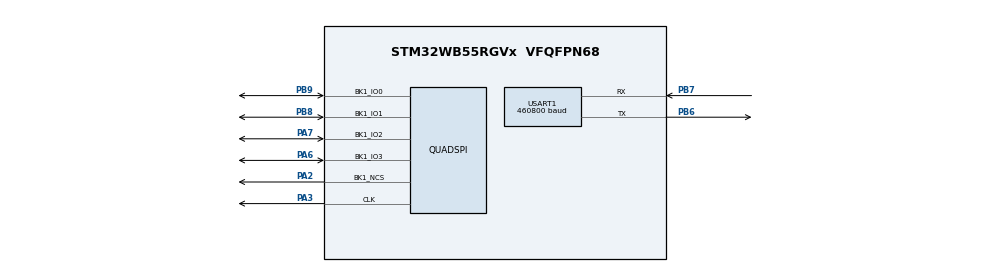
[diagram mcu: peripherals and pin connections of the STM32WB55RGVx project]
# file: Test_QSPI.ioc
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Dma.QUADSPI.1.Direction=DMA_PERIPH_TO_MEMORY
Dma.QUADSPI.1.EventEnable=DISABLE
Dma.QUADSPI.1.Instance=DMA1_Channel2
Dma.QUADSPI.1.MemDataAlignment=DMA_MDATAALIGN_BYTE
Dma.QUADSPI.1.MemInc=DMA_MINC_ENABLE
Dma.QUADSPI.1.Mode=DMA_NORMAL
Dma.QUADSPI.1.PeriphDataAlignment=DMA_PDATAALIGN_BYTE
Dma.QUADSPI.1.PeriphInc=DMA_PINC_DISABLE
Dma.QUADSPI.1.Polarity=HAL_DMAMUX_REQ_GEN_RISING
Dma.QUADSPI.1.Priority=DMA_PRIORITY_LOW
Dma.QUADSPI.1.RequestNumber=1
Dma.QUADSPI.1.SignalID=NONE
Dma.QUADSPI.1.SyncEnable=DISABLE
Dma.QUADSPI.1.SyncPolarity=HAL_DMAMUX_SYNC_NO_EVENT
Dma.QUADSPI.1.SyncRequestNumber=1
Dma.QUADSPI.1.SyncSignalID=NONE
Dma.Request0=USART1_TX
Dma.Request1=QUADSPI
Dma.USART1_TX.0.Direction=DMA_MEMORY_TO_PERIPH
Dma.USART1_TX.0.EventEnable=DISABLE
Dma.USART1_TX.0.Instance=DMA1_Channel1
Dma.USART1_TX.0.MemDataAlignment=DMA_MDATAALIGN_BYTE
Dma.USART1_TX.0.MemInc=DMA_MINC_ENABLE
Dma.USART1_TX.0.Mode=DMA_NORMAL
Dma.USART1_TX.0.PeriphDataAlignment=DMA_PDATAALIGN_BYTE
Dma.USART1_TX.0.PeriphInc=DMA_PINC_DISABLE
Dma.USART1_TX.0.Polarity=HAL_DMAMUX_REQ_GEN_RISING
Dma.USART1_TX.0.Priority=DMA_PRIORITY_LOW
Dma.USART1_TX.0.RequestNumber=1
Dma.USART1_TX.0.SignalID=NONE
Dma.USART1_TX.0.SyncEnable=DISABLE
Dma.USART1_TX.0.SyncPolarity=HAL_DMAMUX_SYNC_NO_EVENT
Dma.USART1_TX.0.SyncRequestNumber=1
Dma.USART1_TX.0.SyncSignalID=NONE
Mcu.Family=STM32WB
Mcu.Name=STM32WB55RGVx
Mcu.Package=VFQFPN68
NVIC.DMA1_Channel1_IRQn=true\:0\:0\:false\:false\:true\:false\:true
NVIC.DMA1_Channel2_IRQn=true\:0\:0\:false\:false\:true\:false\:true
NVIC.LPTIM1_IRQn=true\:0\:0\:false\:false\:true\:true\:true
NVIC.PriorityGroup=NVIC_PRIORITYGROUP_4
NVIC.QUADSPI_IRQn=true\:0\:0\:false\:false\:true\:true\:true
NVIC.TIM1_TRG_COM_TIM17_IRQn=true\:15\:0\:false\:false\:true\:false\:true
NVIC.TimeBase=TIM1_TRG_COM_TIM17_IRQn
NVIC.TimeBaseIP=TIM17
OSC_IN.Mode=HSE-External-Oscillator
OSC_IN.Signal=RCC_OSC_IN
OSC_OUT.Mode=HSE-External-Oscillator
OSC_OUT.Signal=RCC_OSC_OUT
PA2.Mode=Single Bank 1
PA2.Signal=QUADSPI_BK1_NCS
PA3.Mode=Single Bank 1
PA3.Signal=QUADSPI_CLK
PA6.Mode=Single Bank 1
PA6.Signal=QUADSPI_BK1_IO3
PA7.Mode=Single Bank 1
PA7.Signal=QUADSPI_BK1_IO2
PB6.Mode=Asynchronous
PB6.Signal=USART1_TX
PB7.Mode=Asynchronous
PB7.Signal=USART1_RX
PB8.Mode=Single Bank 1
PB8.Signal=QUADSPI_BK1_IO1
PB9.Mode=Single Bank 1
PB9.Signal=QUADSPI_BK1_IO0
PC14-OSC32_IN.Mode=LSE-External-Oscillator
PC14-OSC32_IN.Signal=RCC_OSC32_IN
PC15-OSC32_OUT.Mode=LSE-External-Oscillator
PC15-OSC32_OUT.Signal=RCC_OSC32_OUT
ProjectManager.HeapSize=0x2000
ProjectManager.StackSize=0x2000
ProjectManager.TargetToolchain=STM32CubeIDE
QUADSPI.ClockPrescaler=0
RCC.ADCFreq_Value=128000000
RCC.AHBFreq_Value=32000000
RCC.APB1Freq_Value=32000000
RCC.APB1TimFreq_Value=32000000
RCC.APB2Freq_Value=32000000
RCC.APB2TimFreq_Value=32000000
RCC.APB3Freq_Value=16000000
RCC.CortexFreq_Value=32000000
RCC.HCLKFreq_Value=32000000
RCC.HSE_VALUE=32000000
RCC.HSI48_VALUE=48000000
RCC.HSI_VALUE=16000000
RCC.LPTIM1CLockSelection=RCC_LPTIM1CLKSOURCE_LSI
RCC.MSIClockRange=RCC_MSIRANGE_10
RCC.RTCClockSelection=RCC_RTCCLKSOURCE_LSE
RCC.SMPSCLockSelectionVirtual=RCC_SMPSCLKSOURCE_HSI
RCC.SMPSCLockSelectionVirtualVirtual=RCC_SMPSCLKSOURCE_HSI
RCC.SMPSDivider=1
RCC.SYSCLKFreq_VALUE=32000000
RCC.USBFreq_Value=128000000
RCC.VCOOutputFreq_Value=256000000
USART1.BaudRate=460800
USART1.VirtualMode-Asynchronous=VM_ASYNC
VP_LPTIM1_VS_LPTIM_counterModeInternalClock.Mode=Counts__internal_clock_event_00
VP_SYS_VS_tim17.Mode=TIM17
board=P-NUCLEO-WB55-Nucleo

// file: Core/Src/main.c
/* USER CODE BEGIN Header */
/**
  ******************************************************************************
  * @file           : main.c
  * @brief          : Main program body
  ******************************************************************************
  * @attention
  *
  * <h2><center>&copy; Copyright (c) 2021 STMicroelectronics.
  * All rights reserved.</center></h2>
  *
  * This software component is licensed by ST under BSD 3-Clause license,
  * the "License"; You may not use this file except in compliance with the
  * License. You may obtain a copy of the License at:
  *                        opensource.org/licenses/BSD-3-Clause
  *
  ******************************************************************************
  */
/* USER CODE END Header */
#include <component_storage.h>
#include "main.h"

LPTIM_HandleTypeDef hlptim1;

UART_HandleTypeDef huart1;
DMA_HandleTypeDef hdma_usart1_tx;

void SystemClock_Config(void);
static void MX_GPIO_Init(void);
static void MX_DMA_Init(void);
static void MX_QUADSPI_Init(void);
static void MX_USART1_UART_Init(void);
static void MX_LPTIM1_Init(void);
/* USER CODE BEGIN PFP */
int __io_putchar(int ch)
{
	uint8_t character = ch & 0xFF;
	HAL_UART_Transmit(&huart1, &character, 1, HAL_MAX_DELAY);
	return ch;
}
/* USER CODE END PFP */

/* USER CODE BEGIN 0 */
volatile uint32_t counter = 0;
/* USER CODE END 0 */

int main(void)
{

  /* MCU Configuration--------------------------------------------------------*/

  /* Reset of all peripherals, Initializes the Flash interface and the Systick. */
  HAL_Init();

  /* Configure the system clock */
  SystemClock_Config();

  /* Initialize all configured peripherals */
  MX_GPIO_Init();
  MX_DMA_Init();
  MX_QUADSPI_Init();
  MX_USART1_UART_Init();
  MX_LPTIM1_Init();
  /* USER CODE BEGIN 2 */
//	HAL_LPTIM_PWM_Start_IT(&hlptim1, 32767, 16000);
	COMPONENT_STORAGE_Initialize();

  /* USER CODE END 2 */

  /* Infinite loop */
	while (1)
	{

	}
}

void HAL_LPTIM_AutoReloadMatchCallback(LPTIM_HandleTypeDef *hlptim)
{

}

void SystemClock_Config(void)
{
  RCC_OscInitTypeDef RCC_OscInitStruct = {0};
  RCC_ClkInitTypeDef RCC_ClkInitStruct = {0};
  RCC_PeriphCLKInitTypeDef PeriphClkInitStruct = {0};

  /** Configure the main internal regulator output voltage
  */
  __HAL_PWR_VOLTAGESCALING_CONFIG(PWR_REGULATOR_VOLTAGE_SCALE1);
  /** Initializes the RCC Oscillators according to the specified parameters
  * in the RCC_OscInitTypeDef structure.
  */
  RCC_OscInitStruct.OscillatorType = RCC_OSCILLATORTYPE_HSI|RCC_OSCILLATORTYPE_LSI1
                              |RCC_OSCILLATORTYPE_HSE|RCC_OSCILLATORTYPE_MSI;
  RCC_OscInitStruct.HSEState = RCC_HSE_ON;
  RCC_OscInitStruct.HSIState = RCC_HSI_ON;
  RCC_OscInitStruct.MSIState = RCC_MSI_ON;
  RCC_OscInitStruct.HSICalibrationValue = RCC_HSICALIBRATION_DEFAULT;
  RCC_OscInitStruct.MSICalibrationValue = RCC_MSICALIBRATION_DEFAULT;
  RCC_OscInitStruct.MSIClockRange = RCC_MSIRANGE_10;
  RCC_OscInitStruct.LSIState = RCC_LSI_ON;
  RCC_OscInitStruct.PLL.PLLState = RCC_PLL_NONE;
  if (HAL_RCC_OscConfig(&RCC_OscInitStruct) != HAL_OK)
  {
    Error_Handler();
  }
  /** Configure the SYSCLKSource, HCLK, PCLK1 and PCLK2 clocks dividers
  */
  RCC_ClkInitStruct.ClockType = RCC_CLOCKTYPE_HCLK4|RCC_CLOCKTYPE_HCLK2
                              |RCC_CLOCKTYPE_HCLK|RCC_CLOCKTYPE_SYSCLK
                              |RCC_CLOCKTYPE_PCLK1|RCC_CLOCKTYPE_PCLK2;
  RCC_ClkInitStruct.SYSCLKSource = RCC_SYSCLKSOURCE_MSI;
  RCC_ClkInitStruct.AHBCLKDivider = RCC_SYSCLK_DIV1;
  RCC_ClkInitStruct.APB1CLKDivider = RCC_HCLK_DIV1;
  RCC_ClkInitStruct.APB2CLKDivider = RCC_HCLK_DIV1;
  RCC_ClkInitStruct.AHBCLK2Divider = RCC_SYSCLK_DIV1;
  RCC_ClkInitStruct.AHBCLK4Divider = RCC_SYSCLK_DIV1;

  if (HAL_RCC_ClockConfig(&RCC_ClkInitStruct, FLASH_LATENCY_1) != HAL_OK)
  {
    Error_Handler();
  }
  /** Initializes the peripherals clocks
  */
  PeriphClkInitStruct.PeriphClockSelection = RCC_PERIPHCLK_SMPS|RCC_PERIPHCLK_USART1
                              |RCC_PERIPHCLK_LPTIM1;
  PeriphClkInitStruct.Usart1ClockSelection = RCC_USART1CLKSOURCE_PCLK2;
  PeriphClkInitStruct.Lptim1ClockSelection = RCC_LPTIM1CLKSOURCE_LSI;
  PeriphClkInitStruct.SmpsClockSelection = RCC_SMPSCLKSOURCE_HSI;
  PeriphClkInitStruct.SmpsDivSelection = RCC_SMPSCLKDIV_RANGE0;
  if (HAL_RCCEx_PeriphCLKConfig(&PeriphClkInitStruct) != HAL_OK)
  {
    Error_Handler();
  }
}

static void MX_LPTIM1_Init(void)
{

  hlptim1.Instance = LPTIM1;
  hlptim1.Init.Clock.Source = LPTIM_CLOCKSOURCE_APBCLOCK_LPOSC;
  hlptim1.Init.Clock.Prescaler = LPTIM_PRESCALER_DIV1;
  hlptim1.Init.Trigger.Source = LPTIM_TRIGSOURCE_SOFTWARE;
  hlptim1.Init.OutputPolarity = LPTIM_OUTPUTPOLARITY_HIGH;
  hlptim1.Init.UpdateMode = LPTIM_UPDATE_IMMEDIATE;
  hlptim1.Init.CounterSource = LPTIM_COUNTERSOURCE_INTERNAL;
  hlptim1.Init.Input1Source = LPTIM_INPUT1SOURCE_GPIO;
  hlptim1.Init.Input2Source = LPTIM_INPUT2SOURCE_GPIO;
  if (HAL_LPTIM_Init(&hlptim1) != HAL_OK)
  {
    Error_Handler();
  }

}

static void MX_QUADSPI_Init(void)
{

  /* QUADSPI parameter configuration*/

}

static void MX_USART1_UART_Init(void)
{

  huart1.Instance = USART1;
  huart1.Init.BaudRate = 460800;
  huart1.Init.WordLength = UART_WORDLENGTH_8B;
  huart1.Init.StopBits = UART_STOPBITS_1;
  huart1.Init.Parity = UART_PARITY_NONE;
  huart1.Init.Mode = UART_MODE_TX_RX;
  huart1.Init.HwFlowCtl = UART_HWCONTROL_NONE;
  huart1.Init.OverSampling = UART_OVERSAMPLING_16;
  huart1.Init.OneBitSampling = UART_ONE_BIT_SAMPLE_DISABLE;
  huart1.Init.ClockPrescaler = UART_PRESCALER_DIV1;
  huart1.AdvancedInit.AdvFeatureInit = UART_ADVFEATURE_NO_INIT;
  if (HAL_UART_Init(&huart1) != HAL_OK)
  {
    Error_Handler();
  }
  if (HAL_UARTEx_SetTxFifoThreshold(&huart1, UART_TXFIFO_THRESHOLD_1_8) != HAL_OK)
  {
    Error_Handler();
  }
  if (HAL_UARTEx_SetRxFifoThreshold(&huart1, UART_RXFIFO_THRESHOLD_1_8) != HAL_OK)
  {
    Error_Handler();
  }
  if (HAL_UARTEx_DisableFifoMode(&huart1) != HAL_OK)
  {
    Error_Handler();
  }

}

static void MX_DMA_Init(void)
{

  /* DMA controller clock enable */
  __HAL_RCC_DMAMUX1_CLK_ENABLE();
  __HAL_RCC_DMA1_CLK_ENABLE();

  /* DMA interrupt init */
  /* DMA1_Channel1_IRQn interrupt configuration */
  HAL_NVIC_SetPriority(DMA1_Channel1_IRQn, 0, 0);
  HAL_NVIC_EnableIRQ(DMA1_Channel1_IRQn);
  /* DMA1_Channel2_IRQn interrupt configuration */
  HAL_NVIC_SetPriority(DMA1_Channel2_IRQn, 0, 0);
  HAL_NVIC_EnableIRQ(DMA1_Channel2_IRQn);

}

static void MX_GPIO_Init(void)
{

  /* GPIO Ports Clock Enable */
  __HAL_RCC_GPIOC_CLK_ENABLE();
  __HAL_RCC_GPIOB_CLK_ENABLE();
  __HAL_RCC_GPIOA_CLK_ENABLE();

}

void HAL_TIM_PeriodElapsedCallback(TIM_HandleTypeDef *htim)
{
  if (htim->Instance == TIM17) {
    HAL_IncTick();
  }
}

void Error_Handler(void)
{
  __disable_irq();
  while (1)
  {
  }
}

/************************ (C) COPYRIGHT STMicroelectronics *****END OF FILE****/
